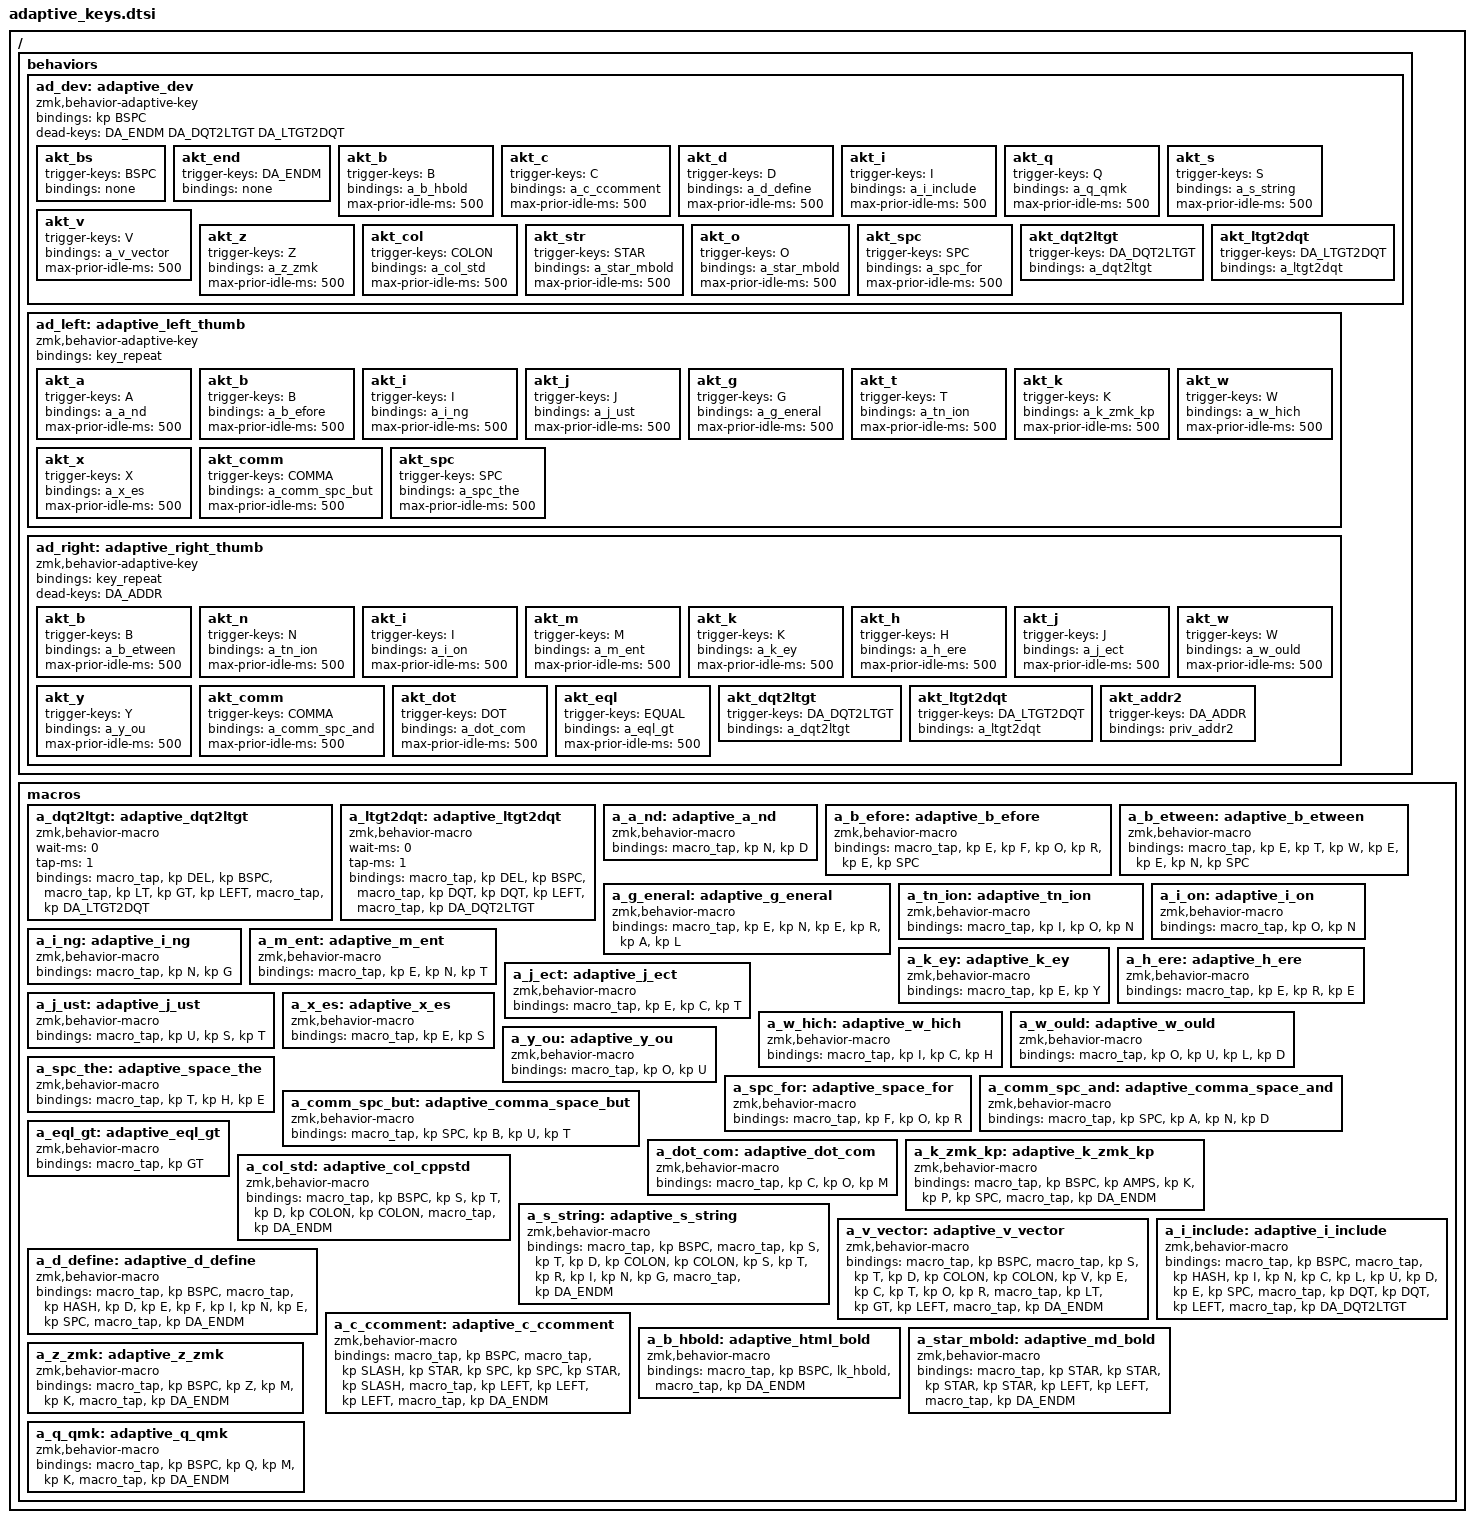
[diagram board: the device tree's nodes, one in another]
/ {
    behaviors {
        ad_dev: adaptive_dev {
            compatible = "zmk,behavior-adaptive-key";
            #binding-cells = <0>;
            bindings = <&kp BSPC>;
            dead-keys = <DA_ENDM DA_DQT2LTGT DA_LTGT2DQT>;

            akt_bs  { trigger-keys = <BSPC>;  bindings = <&none>; };
            akt_end { trigger-keys = <DA_ENDM>; bindings = <&none>; };
            akt_b   { trigger-keys = <B>;     bindings = <&a_b_hbold>;      max-prior-idle-ms = <500>; };
            akt_c   { trigger-keys = <C>;     bindings = <&a_c_ccomment>;   max-prior-idle-ms = <500>; };
            akt_d   { trigger-keys = <D>;     bindings = <&a_d_define>;     max-prior-idle-ms = <500>; };
            akt_i   { trigger-keys = <I>;     bindings = <&a_i_include>;    max-prior-idle-ms = <500>; };
            akt_q   { trigger-keys = <Q>;     bindings = <&a_q_qmk>;        max-prior-idle-ms = <500>; };
            akt_s   { trigger-keys = <S>;     bindings = <&a_s_string>;     max-prior-idle-ms = <500>; };
            akt_v   { trigger-keys = <V>;     bindings = <&a_v_vector>;     max-prior-idle-ms = <500>; };
            akt_z   { trigger-keys = <Z>;     bindings = <&a_z_zmk>;        max-prior-idle-ms = <500>; };
            akt_col { trigger-keys = <COLON>; bindings = <&a_col_std>;      max-prior-idle-ms = <500>; };
            akt_str { trigger-keys = <STAR>;  bindings = <&a_star_mbold>;   max-prior-idle-ms = <500>; };
            akt_o   { trigger-keys = <O>;     bindings = <&a_star_mbold>;   max-prior-idle-ms = <500>; }; // position of star on main
            akt_spc { trigger-keys = <SPC>;   bindings = <&a_spc_for>;      max-prior-idle-ms = <500>; };
            akt_dqt2ltgt { trigger-keys = <DA_DQT2LTGT>; bindings = <&a_dqt2ltgt>; };
            akt_ltgt2dqt { trigger-keys = <DA_LTGT2DQT>; bindings = <&a_ltgt2dqt>; };
        };

        ad_left: adaptive_left_thumb {
            compatible = "zmk,behavior-adaptive-key";
            #binding-cells = <0>;
            bindings = <&key_repeat>;

            akt_a   { trigger-keys = <A>;     bindings = <&a_a_nd>;         max-prior-idle-ms = <500>; };
            akt_b   { trigger-keys = <B>;     bindings = <&a_b_efore>;      max-prior-idle-ms = <500>; };
            akt_i   { trigger-keys = <I>;     bindings = <&a_i_ng>;         max-prior-idle-ms = <500>; };
            akt_j   { trigger-keys = <J>;     bindings = <&a_j_ust>;        max-prior-idle-ms = <500>; };
            akt_g   { trigger-keys = <G>;     bindings = <&a_g_eneral>;     max-prior-idle-ms = <500>; };
            akt_t   { trigger-keys = <T>;     bindings = <&a_tn_ion>;       max-prior-idle-ms = <500>; };
            akt_k   { trigger-keys = <K>;     bindings = <&a_k_zmk_kp>;     max-prior-idle-ms = <500>; };
            akt_w   { trigger-keys = <W>;     bindings = <&a_w_hich>;       max-prior-idle-ms = <500>; };
            akt_x   { trigger-keys = <X>;     bindings = <&a_x_es>;         max-prior-idle-ms = <500>; };
            akt_comm{ trigger-keys = <COMMA>; bindings = <&a_comm_spc_but>; max-prior-idle-ms = <500>; };
            akt_spc { trigger-keys = <SPC>;   bindings = <&a_spc_the>;      max-prior-idle-ms = <500>; };
        };

        ad_right: adaptive_right_thumb {
            compatible = "zmk,behavior-adaptive-key";
            #binding-cells = <0>;
            bindings = <&key_repeat>;
            dead-keys = <DA_ADDR>;

            akt_b   { trigger-keys = <B>;     bindings = <&a_b_etween>;     max-prior-idle-ms = <500>; };
            akt_n   { trigger-keys = <N>;     bindings = <&a_tn_ion>;       max-prior-idle-ms = <500>; };
            akt_i   { trigger-keys = <I>;     bindings = <&a_i_on>;         max-prior-idle-ms = <500>; };
            akt_m   { trigger-keys = <M>;     bindings = <&a_m_ent>;        max-prior-idle-ms = <500>; };
            akt_k   { trigger-keys = <K>;     bindings = <&a_k_ey>;         max-prior-idle-ms = <500>; };
            akt_h   { trigger-keys = <H>;     bindings = <&a_h_ere>;        max-prior-idle-ms = <500>; };
            akt_j   { trigger-keys = <J>;     bindings = <&a_j_ect>;        max-prior-idle-ms = <500>; };
            akt_w   { trigger-keys = <W>;     bindings = <&a_w_ould>;       max-prior-idle-ms = <500>; };
            akt_y   { trigger-keys = <Y>;     bindings = <&a_y_ou>;         max-prior-idle-ms = <500>; };
            akt_comm{ trigger-keys = <COMMA>; bindings = <&a_comm_spc_and>; max-prior-idle-ms = <500>; };
            akt_dot { trigger-keys = <DOT>;   bindings = <&a_dot_com>;      max-prior-idle-ms = <500>; };
            akt_eql { trigger-keys = <EQUAL>; bindings = <&a_eql_gt>;       max-prior-idle-ms = <500>; };
            akt_dqt2ltgt { trigger-keys = <DA_DQT2LTGT>; bindings = <&a_dqt2ltgt>; };
            akt_ltgt2dqt { trigger-keys = <DA_LTGT2DQT>; bindings = <&a_ltgt2dqt>; };
            akt_addr2 { trigger-keys = <DA_ADDR>; bindings = <&priv_addr2>; };
        };

    };

    macros {
        a_dqt2ltgt: adaptive_dqt2ltgt {
            compatible = "zmk,behavior-macro";
            #binding-cells = <0>;
            wait-ms = <0>;
            tap-ms = <1>;
            bindings
                = <&macro_tap &kp DEL &kp BSPC>
                , <&macro_tap &kp LT &kp GT &kp LEFT>
                , <&macro_tap &kp DA_LTGT2DQT>
                ;
        };
        a_ltgt2dqt: adaptive_ltgt2dqt {
            compatible = "zmk,behavior-macro";
            #binding-cells = <0>;
            wait-ms = <0>;
            tap-ms = <1>;
            bindings
                = <&macro_tap &kp DEL &kp BSPC>
                , <&macro_tap &kp DQT &kp DQT &kp LEFT>
                , <&macro_tap &kp DA_DQT2LTGT>
                ;
        };
        a_a_nd: adaptive_a_nd {
            compatible = "zmk,behavior-macro";
            #binding-cells = <0>;
            bindings = <&macro_tap &kp N &kp D>;
        };
        a_b_efore: adaptive_b_efore {
            compatible = "zmk,behavior-macro";
            #binding-cells = <0>;
            bindings = <&macro_tap &kp E &kp F &kp O &kp R &kp E &kp SPC>;
        };
        a_b_etween: adaptive_b_etween {
            compatible = "zmk,behavior-macro";
            #binding-cells = <0>;
            bindings = <&macro_tap &kp E &kp T &kp W &kp E &kp E &kp N &kp SPC>;
        };
        a_g_eneral: adaptive_g_eneral {
            compatible = "zmk,behavior-macro";
            #binding-cells = <0>;
            bindings = <&macro_tap &kp E &kp N &kp E &kp R &kp A &kp L>;
        };
        a_tn_ion: adaptive_tn_ion {
            compatible = "zmk,behavior-macro";
            #binding-cells = <0>;
            bindings = <&macro_tap &kp I &kp O &kp N>;
        };
        a_i_on: adaptive_i_on {
            compatible = "zmk,behavior-macro";
            #binding-cells = <0>;
            bindings = <&macro_tap &kp O &kp N>;
        };
        a_i_ng: adaptive_i_ng {
            compatible = "zmk,behavior-macro";
            #binding-cells = <0>;
            bindings = <&macro_tap &kp N &kp G>;
        };
        a_m_ent: adaptive_m_ent {
            compatible = "zmk,behavior-macro";
            #binding-cells = <0>;
            bindings = <&macro_tap &kp E &kp N &kp T>;
        };
        a_k_ey: adaptive_k_ey {
            compatible = "zmk,behavior-macro";
            #binding-cells = <0>;
            bindings = <&macro_tap &kp E &kp Y>;
        };
        a_h_ere: adaptive_h_ere {
            compatible = "zmk,behavior-macro";
            #binding-cells = <0>;
            bindings = <&macro_tap &kp E &kp R &kp E>;
        };
        a_j_ect: adaptive_j_ect {
            compatible = "zmk,behavior-macro";
            #binding-cells = <0>;
            bindings = <&macro_tap &kp E &kp C &kp T>;
        };
        a_j_ust: adaptive_j_ust {
            compatible = "zmk,behavior-macro";
            #binding-cells = <0>;
            bindings = <&macro_tap &kp U &kp S &kp T>;
        };
        a_w_hich: adaptive_w_hich {
            compatible = "zmk,behavior-macro";
            #binding-cells = <0>;
            bindings = <&macro_tap &kp I &kp C &kp H>;
        };
        a_w_ould: adaptive_w_ould {
            compatible = "zmk,behavior-macro";
            #binding-cells = <0>;
            bindings = <&macro_tap &kp O &kp U &kp L &kp D>;
        };
        a_x_es: adaptive_x_es {
            compatible = "zmk,behavior-macro";
            #binding-cells = <0>;
            bindings = <&macro_tap &kp E &kp S>;
        };
        a_y_ou: adaptive_y_ou {
            compatible = "zmk,behavior-macro";
            #binding-cells = <0>;
            bindings = <&macro_tap &kp O &kp U>;
        };
        a_spc_the: adaptive_space_the {
            compatible = "zmk,behavior-macro";
            #binding-cells = <0>;
            bindings = <&macro_tap &kp T &kp H &kp E>;
        };
        a_spc_for: adaptive_space_for {
            compatible = "zmk,behavior-macro";
            #binding-cells = <0>;
            bindings = <&macro_tap &kp F &kp O &kp R>;
        };
        a_comm_spc_and: adaptive_comma_space_and {
            compatible = "zmk,behavior-macro";
            #binding-cells = <0>;
            bindings = <&macro_tap &kp SPC &kp A &kp N &kp D>;
        };
        a_comm_spc_but: adaptive_comma_space_but {
            compatible = "zmk,behavior-macro";
            #binding-cells = <0>;
            bindings = <&macro_tap &kp SPC &kp B &kp U &kp T>;
        };
        a_eql_gt: adaptive_eql_gt {
            compatible = "zmk,behavior-macro";
            #binding-cells = <0>;
            bindings = <&macro_tap &kp GT>;
        };
        a_dot_com: adaptive_dot_com {
            compatible = "zmk,behavior-macro";
            #binding-cells = <0>;
            bindings = <&macro_tap &kp C &kp O &kp M>;
        };

        a_k_zmk_kp: adaptive_k_zmk_kp {
            compatible = "zmk,behavior-macro";
            #binding-cells = <0>;
            bindings = <&macro_tap &kp BSPC &kp AMPS &kp K &kp P &kp SPC>
                     , <&macro_tap &kp DA_ENDM>;
        };
        a_col_std: adaptive_col_cppstd {
            compatible = "zmk,behavior-macro";
            #binding-cells = <0>;
            bindings = <&macro_tap &kp BSPC &kp S &kp T &kp D &kp COLON &kp COLON>
                     , <&macro_tap &kp DA_ENDM>;
        };
        a_s_string: adaptive_s_string {
            compatible = "zmk,behavior-macro";
            #binding-cells = <0>;
            bindings = <&macro_tap &kp BSPC>
                     , <&macro_tap &kp S &kp T &kp D &kp COLON &kp COLON &kp S &kp T &kp R &kp I &kp N &kp G>
                     , <&macro_tap &kp DA_ENDM>;
        };
        a_v_vector: adaptive_v_vector {
            compatible = "zmk,behavior-macro";
            #binding-cells = <0>;
            bindings = <&macro_tap &kp BSPC>
                     , <&macro_tap &kp S &kp T &kp D &kp COLON &kp COLON &kp V &kp E &kp C &kp T &kp O &kp R>
                     , <&macro_tap &kp LT &kp GT &kp LEFT>
                     , <&macro_tap &kp DA_ENDM>;
        };
        a_i_include: adaptive_i_include {
            compatible = "zmk,behavior-macro";
            #binding-cells = <0>;
            bindings = <&macro_tap &kp BSPC>
                     , <&macro_tap &kp HASH &kp I &kp N &kp C &kp L &kp U &kp D &kp E &kp SPC>
                     , <&macro_tap &kp DQT &kp DQT &kp LEFT>
                     , <&macro_tap &kp DA_DQT2LTGT>;
        };
        a_d_define: adaptive_d_define {
            compatible = "zmk,behavior-macro";
            #binding-cells = <0>;
            bindings = <&macro_tap &kp BSPC>
                     , <&macro_tap &kp HASH &kp D &kp E &kp F &kp I &kp N &kp E &kp SPC>
                     , <&macro_tap &kp DA_ENDM>;
        };
        a_c_ccomment: adaptive_c_ccomment {
            compatible = "zmk,behavior-macro";
            #binding-cells = <0>;
            bindings = <&macro_tap &kp BSPC>
                     , <&macro_tap &kp SLASH &kp STAR &kp SPC &kp SPC &kp STAR &kp SLASH>
                     , <&macro_tap &kp LEFT &kp LEFT &kp LEFT>
                     , <&macro_tap &kp DA_ENDM>;
        };
        a_b_hbold: adaptive_html_bold {
            compatible = "zmk,behavior-macro";
            #binding-cells = <0>;
            bindings = <&macro_tap &kp BSPC &lk_hbold>
                     , <&macro_tap &kp DA_ENDM>;
        };
        a_star_mbold: adaptive_md_bold {
            compatible = "zmk,behavior-macro";
            #binding-cells = <0>;
            bindings = <&macro_tap &kp STAR &kp STAR &kp STAR &kp STAR &kp LEFT &kp LEFT>
                     , <&macro_tap &kp DA_ENDM>;
        };
        a_z_zmk: adaptive_z_zmk {
            compatible = "zmk,behavior-macro";
            #binding-cells = <0>;
            bindings = <&macro_tap &kp BSPC &kp Z &kp M &kp K>
                     , <&macro_tap &kp DA_ENDM>;
        };
        a_q_qmk: adaptive_q_qmk {
            compatible = "zmk,behavior-macro";
            #binding-cells = <0>;
            bindings = <&macro_tap &kp BSPC &kp Q &kp M &kp K>
                     , <&macro_tap &kp DA_ENDM>;
        };


    };
};
